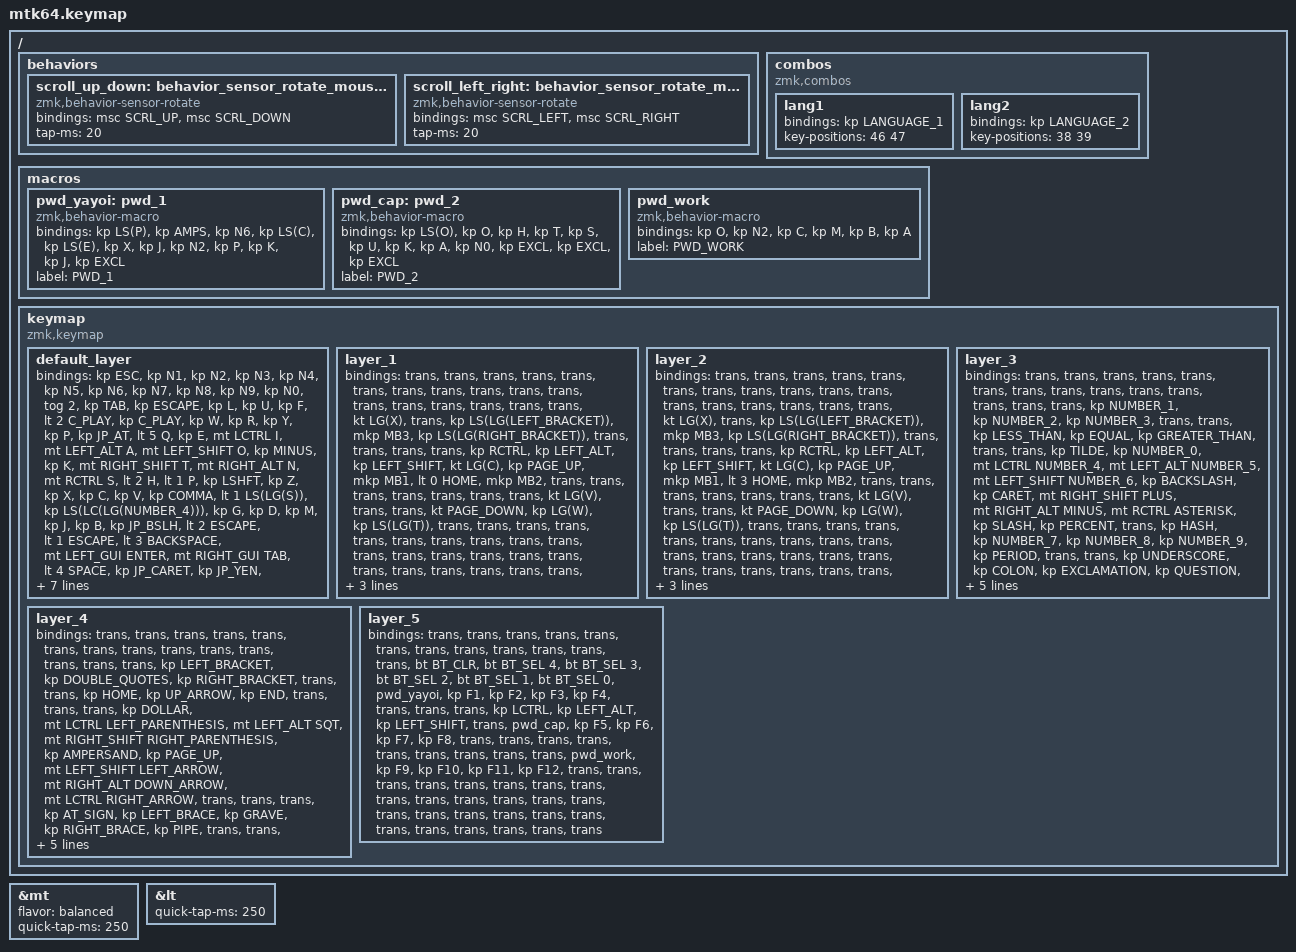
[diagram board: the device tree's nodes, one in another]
#include <behaviors.dtsi>
#include <dt-bindings/zmk/bt.h>
#include <dt-bindings/zmk/keys.h>
#include <dt-bindings/zmk/pointing.h>
#include "keycode_japanese.h"

// スクロール量の設定

#define ZMK_POINTING_DEFAULT_SCRL_VAL 100

&mt {
    flavor = "balanced";
    quick-tap-ms = <250>;
};

&lt { quick-tap-ms = <250>; };

/ {
    behaviors {
        // 垂直スクロール用のbehaviorの設定

        scroll_up_down: behavior_sensor_rotate_mouse_wheel_up_down {
            compatible = "zmk,behavior-sensor-rotate";
            #sensor-binding-cells = <0>;
            bindings = <&msc SCRL_UP>, <&msc SCRL_DOWN>;

            tap-ms = <20>; // スクロールのタップ時間
        };

        // 水平スクロール用のbehaviorの設定

        scroll_left_right: behavior_sensor_rotate_mouse_wheel_left_right {
            compatible = "zmk,behavior-sensor-rotate";
            #sensor-binding-cells = <0>;
            bindings = <&msc SCRL_LEFT>, <&msc SCRL_RIGHT>;

            tap-ms = <20>; // スクロールのタップ時間
        };
    };
};

/ {
    combos {
        compatible = "zmk,combos";

        lang1 {
            bindings = <&kp LANGUAGE_1>;
            key-positions = <46 47>;
        };

        lang2 {
            bindings = <&kp LANGUAGE_2>;
            key-positions = <38 39>;
        };
    };

    macros {
        pwd_yayoi: pwd_1 {
            compatible = "zmk,behavior-macro";
            #binding-cells = <0>;
            bindings = <&kp LS(P) &kp AMPS &kp N6 &kp LS(C) &kp LS(E) &kp X &kp J &kp N2 &kp P &kp K &kp J &kp EXCL>;
            label = "PWD_1";
        };

        pwd_cap: pwd_2 {
            compatible = "zmk,behavior-macro";
            #binding-cells = <0>;
            bindings = <&kp LS(O) &kp O &kp H &kp T &kp S &kp U &kp K &kp A &kp N0 &kp EXCL &kp EXCL &kp EXCL>;
            label = "PWD_2";
        };

        pwd_work: pwd_work {
            compatible = "zmk,behavior-macro";
            #binding-cells = <0>;
            bindings = <&kp O &kp N2 &kp C &kp M &kp B &kp A>;
            label = "PWD_WORK";
        };
    };

    keymap {
        compatible = "zmk,keymap";

        default_layer {
            bindings = <
&kp ESC  &kp N1  &kp N2  &kp N3  &kp N4  &kp N5  &kp N6  &kp N7  &kp N8  &kp N9  &kp N0  &tog 2  &kp TAB  &kp ESCAPE  &kp L  &kp U  &kp F  &lt 2 C_PLAY  &kp C_PLAY  &kp W  &kp R  &kp Y  &kp P  &kp JP_AT  &lt 5 Q  &kp E  &mt LCTRL I  &mt LEFT_ALT A  &mt LEFT_SHIFT O  &kp MINUS  &kp K  &mt RIGHT_SHIFT T  &mt RIGHT_ALT N  &mt RCTRL S  &lt 2 H  &lt 1 P  &kp LSHFT  &kp Z  &kp X  &kp C  &kp V  &kp COMMA  &lt 1 LS(LG(S))  &kp LS(LC(LG(NUMBER_4)))  &kp G  &kp D  &kp M  &kp J  &kp B  &kp JP_BSLH  &lt 2 ESCAPE  &lt 1 ESCAPE  &lt 3 BACKSPACE  &mt LEFT_GUI ENTER  &mt RIGHT_GUI TAB  &lt 4 SPACE  &kp JP_CARET  &kp JP_YEN  &kp LG(N0)  &kp C_MUTE  &lt 1 LANGUAGE_1  &lt 1 LANGUAGE_2  &kp ENTER  &tog 0  &lt 2 ESCAPE  &mt RIGHT_GUI TAB  &mo 1  &mo 0  &mo 0  &mo 1  &mo 0  &mo 0  &mo 1  &mo 0  &mo 0
            >;

            sensor-bindings =
                <&inc_dec_kp LG(MINUS) LG(PLUS)>,
                <&inc_dec_kp C_VOLUME_DOWN C_VOLUME_UP>;
        };

        layer_1 {
            bindings = <
&trans  &trans  &trans  &trans  &trans  &trans  &trans  &trans  &trans  &trans  &trans  &trans  &trans  &trans  &trans  &trans  &trans  &kt LG(X)  &trans  &kp LS(LG(LEFT_BRACKET))  &mkp MB3  &kp LS(LG(RIGHT_BRACKET))  &trans  &trans  &trans  &trans  &kp RCTRL  &kp LEFT_ALT  &kp LEFT_SHIFT  &kt LG(C)  &kp PAGE_UP  &mkp MB1  &lt 0 HOME  &mkp MB2  &trans  &trans  &trans  &trans  &trans  &trans  &trans  &kt LG(V)  &trans  &trans  &kt PAGE_DOWN  &kp LG(W)  &kp LS(LG(T))  &trans  &trans  &trans  &trans  &trans  &trans  &trans  &trans  &trans  &trans  &trans  &trans  &trans  &trans  &trans  &trans  &trans  &trans  &trans  &trans  &trans  &trans  &trans  &trans  &trans  &trans  &trans  &trans
            >;

            sensor-bindings = <
                &inc_dec_kp TAB LC(TAB) 
                &inc_dec_kp PG_UP PG_DN
            >;
        };

        layer_2 {
            bindings = <
&trans  &trans  &trans  &trans  &trans  &trans  &trans  &trans  &trans  &trans  &trans  &trans  &trans  &trans  &trans  &trans  &trans  &kt LG(X)  &trans  &kp LS(LG(LEFT_BRACKET))  &mkp MB3  &kp LS(LG(RIGHT_BRACKET))  &trans  &trans  &trans  &trans  &kp RCTRL  &kp LEFT_ALT  &kp LEFT_SHIFT  &kt LG(C)  &kp PAGE_UP  &mkp MB1  &lt 3 HOME  &mkp MB2  &trans  &trans  &trans  &trans  &trans  &trans  &trans  &kt LG(V)  &trans  &trans  &kt PAGE_DOWN  &kp LG(W)  &kp LS(LG(T))  &trans  &trans  &trans  &trans  &trans  &trans  &trans  &trans  &trans  &trans  &trans  &trans  &trans  &trans  &trans  &trans  &trans  &trans  &trans  &trans  &trans  &trans  &trans  &trans  &trans  &trans  &trans  &trans
            >;

            sensor-bindings = <
                &inc_dec_kp TAB LC(TAB) 
                &inc_dec_kp PG_UP PG_DN
            >;
        };

        layer_3 {
            bindings = <
&trans  &trans  &trans  &trans  &trans  &trans  &trans  &trans  &trans  &trans  &trans  &trans  &trans  &trans  &kp NUMBER_1  &kp NUMBER_2  &kp NUMBER_3  &trans  &trans  &kp LESS_THAN  &kp EQUAL  &kp GREATER_THAN  &trans  &trans  &kp TILDE  &kp NUMBER_0  &mt LCTRL NUMBER_4  &mt LEFT_ALT NUMBER_5  &mt LEFT_SHIFT NUMBER_6  &kp BACKSLASH  &kp CARET  &mt RIGHT_SHIFT PLUS  &mt RIGHT_ALT MINUS  &mt RCTRL ASTERISK  &kp SLASH  &kp PERCENT  &trans  &kp HASH  &kp NUMBER_7  &kp NUMBER_8  &kp NUMBER_9  &kp PERIOD  &trans  &trans  &kp UNDERSCORE  &kp COLON  &kp EXCLAMATION  &kp QUESTION  &kp SEMICOLON  &trans  &trans  &trans  &trans  &trans  &trans  &trans  &trans  &trans  &trans  &trans  &trans  &trans  &trans  &trans  &trans  &trans  &trans  &trans  &trans  &trans  &trans  &trans  &trans  &trans  &trans
            >;
        };

        layer_4 {
            bindings = <
&trans  &trans  &trans  &trans  &trans  &trans  &trans  &trans  &trans  &trans  &trans  &trans  &trans  &trans  &kp LEFT_BRACKET  &kp DOUBLE_QUOTES  &kp RIGHT_BRACKET  &trans  &trans  &kp HOME  &kp UP_ARROW  &kp END  &trans  &trans  &trans  &kp DOLLAR  &mt LCTRL LEFT_PARENTHESIS  &mt LEFT_ALT SQT  &mt RIGHT_SHIFT RIGHT_PARENTHESIS  &kp AMPERSAND  &kp PAGE_UP  &mt LEFT_SHIFT LEFT_ARROW  &mt RIGHT_ALT DOWN_ARROW  &mt LCTRL RIGHT_ARROW  &trans  &trans  &trans  &kp AT_SIGN  &kp LEFT_BRACE  &kp GRAVE  &kp RIGHT_BRACE  &kp PIPE  &trans  &trans  &kp PAGE_DOWN  &trans  &trans  &trans  &trans  &trans  &trans  &trans  &trans  &trans  &trans  &trans  &trans  &trans
            >;

            sensor-bindings = <
                &scroll_left_right
                &scroll_up_down
            >;
        };

        layer_5 {
            bindings = <
&trans  &trans  &trans  &trans  &trans  &trans  &trans  &trans  &trans  &trans  &trans  &trans  &bt BT_CLR  &bt BT_SEL 4  &bt BT_SEL 3  &bt BT_SEL 2  &bt BT_SEL 1  &bt BT_SEL 0  &pwd_yayoi  &kp F1  &kp F2  &kp F3  &kp F4  &trans  &trans  &trans  &kp LCTRL  &kp LEFT_ALT  &kp LEFT_SHIFT  &trans  &pwd_cap  &kp F5  &kp F6  &kp F7  &kp F8  &trans  &trans  &trans  &trans  &trans  &trans  &trans  &trans  &trans  &pwd_work  &kp F9  &kp F10  &kp F11  &kp F12  &trans  &trans  &trans  &trans  &trans  &trans  &trans  &trans  &trans  &trans  &trans  &trans  &trans  &trans  &trans  &trans  &trans  &trans  &trans  &trans  &trans  &trans  &trans  &trans  &trans  &trans
            >;
        };
    };
};
